# ISD91200B_v1 register map
File version: 1.0
Registers are 32-bit, read-write, reset 0x0 unless marked. A register's access mark holds for its fields unless they carry their own. Offsets are from the block's base; [hi:lo] are bit positions; 'fields as' and 'values as' point back to an identical list.

## CLK — CLK Register Map
Base 0x50000200
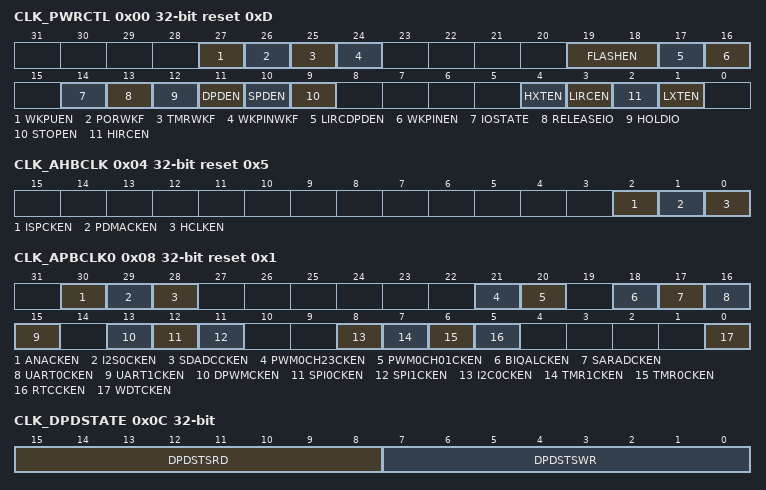
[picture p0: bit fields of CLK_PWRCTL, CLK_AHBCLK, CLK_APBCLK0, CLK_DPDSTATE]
0x00 CLK_PWRCTL reset 0xD (reset mask 0xFFFFFF) — System Power Control Register
  [27] WKPUEN — Wakeup Pin Pull-up Control. This signal is latched in deep power down and preserved.
    0=pull-up enable; 1=tri-state (default)
  [26] PORWKF — POR Wakeup Flag. Read Only. This flag indicates that wakeup of device was requested with a power-on reset. Flag is cleared when DPD mode is entered.
  [25] TMRWKF — Timer Wakeup Flag. Read Only. This flag indicates that wakeup of device was requested with TIMER count of the 10khz oscillator. Flag is cleared when DPD mode is entered.
  [24] WKPINWKF — Pin Wakeup Flag. Read Only. This flag indicates that wakeup of device was requested with a high to low transition of the WAKEUP pin. Flag is cleared when DPD mode is entered.
  [19:18] FLASHEN — Flash ROM Control Enable/Disable. Bit [19]: for Stop mode operation. Bit [18]: for Sleep mode operation. 1: Turn off flash. 0: Normal. Note: It takes 10us to turn on the flash to normal
  [17] LIRCDPDEN — OSC10k Enabled Control. Determines whether OSC10k is enabled in DPD mode. If OSC10k is disabled, device cannot wake from DPD with SELWKTMR delay.
    0=enabled; 1=disabled
  [16] WKPINEN — Wakeup Pin Enabled Control. Determines whether WAKEUP pin is enabled in DPD mode.
    0=enabled; 1=disabled
  [14] IOSTATE — '1': IO held from SPD '0': IO released.
  [13] RELEASEIO — Write '1' to this bit to release IO state after exiting SPD if hold request was made with the HOLD_IO bit.
  [12] HOLDIO — When entering SPD mode, IO state is automatically held If this bit is set to '1' then this sate upon resuming full power mode will be hold until the RELEASE_IO bit is written '1'
  [11] DPDEN — Deep Power Down (DPD) Bit. Set to '1' and issue WFI/WFE instruction to enter DPD mode.
  [10] SPDEN — Standby Power Down (SPD) Bit. Set to '1' and issue WFI/WFE instruction to enter SPD mode.
  [9] STOPEN — Stop. Set to '1' and issue WFI/WFE instruction to enter STOP mode.
  [4] HXTEN — HXT Oscillator Enable Bit
    0=disable (default); 1=enable
  [3] LIRCEN — LIRC Oscillator Enable Bit
    0=disable; 1=enable (default)
  [2] HIRCEN — HIRC Oscillator Enable Bit
    0=disable; 1=enable (default)
  [1] LXTEN — External 32.768 KHz Crystal Enable Bit
    0=disable (default); 1=enable
0x04 CLK_AHBCLK reset 0x5 — AHB Device Clock Enable Control Register
  [2] ISPCKEN — Flash ISP Controller Clock Enable Control
    0=To disable the Flash ISP engine clock; 1=To enable the Flash ISP engine clock
  [1] PDMACKEN — PDMA Controller Clock Enable Control
    0=To disable the PDMA engine clock; 1=To enable the PDMA engine clock
  [0] HCLKEN — CPU Clock Enable (HCLK). Must be left as 1 for normal operation.
0x08 CLK_APBCLK0 reset 0x1 — APB Device Clock Enable Control Register
  [all] fields
    0=Disable; 1=Enable
  [30] ANACKEN — Analog Block Clock Enable Control
  [29] I2S0CKEN — I2S Clock Enable Control
  [28] SDADCCKEN — Delta-Sigma Analog-digital-converter (ADC) Enable Control
  [21] PWM0CH23CKEN — PWM0CH2 and PWM0CH3 Block Clock Enable Control
  [20] PWM0CH01CKEN — PWM0CH0 and PWM0CH1 Block Clock Enable Control
  [18] BIQALCKEN — BIQ and ALC Clock Enable Control
  [17] SARADCKEN — SAR Analog-digital-converter (ADC) Clock Enable Control
  [16] UART0CKEN — UART0 Clock Enable Control
  [15] UART1CKEN — UART1 Clock Enable Control
  [13] DPWMCKEN — Differential PWM Speaker Driver Clock Enable Control
  [12] SPI0CKEN — SPI0 Clock Enable Control
  [11] SPI1CKEN — SPI1 Clock Enable Control
  [8] I2C0CKEN — I2C0 Clock Enable Control
  [7] TMR1CKEN — Timer1 Clock Enable Control
  [6] TMR0CKEN — Timer0 Clock Enable Control
  [5] RTCCKEN — Real-time-clock APB Interface Clock Control
  [0] WDTCKEN — Watchdog Clock Enable Control
0x0C CLK_DPDSTATE (reset mask 0xFFFF00FF) — Deep Power Down State Register
  [15:8] DPDSTSRD — DPD State Read Back. Read back of CLK_DPDSTATE register. This register was preserved from last DPD event .
  [7:0] DPDSTSWR — DPD State Write Register. Read back of CLK_DPDSTATE register. This register was preserved from last DPD event .
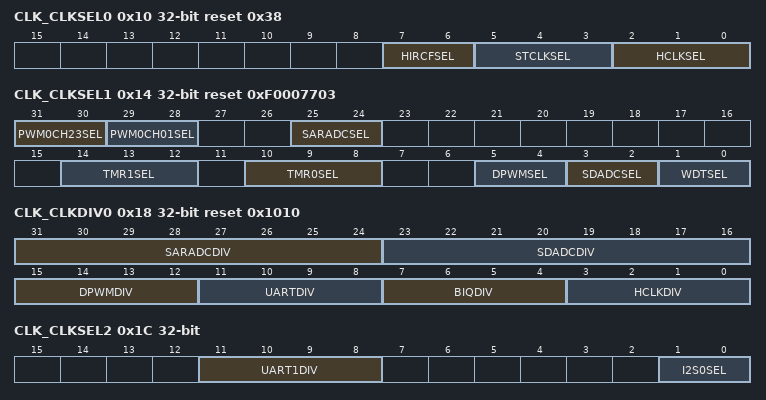
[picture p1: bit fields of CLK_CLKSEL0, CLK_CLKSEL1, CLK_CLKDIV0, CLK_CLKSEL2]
0x10 CLK_CLKSEL0 reset 0x38 — Clock Source Select Control Register 0
  [7:6] HIRCFSEL — High Frequency RC Oscilltor Frequency Select Register. These bits are protected, to write to bits first perform the unlock sequence.
    0=Trim for 49.152MHz selected; 1=Trim for 32.768MHz selected; 2=Trim for reserved
  [5:3] STCLKSEL — MCU Cortex_M0 SYST Clock Source Select. These bits are protected, to write to bits first perform the unlock sequence. Note that to use STCLKSEL as source of SysTic timer the CLKSRC bit of SYST_CSR must be set to 0.
    0=clock source from LIRC; 1=clock source from LXT. clock source from HCLK÷2 (Default); 2=clock source from LIRC divided by 2; 3=clock source from HIRC divided by 2
  [2:0] HCLKSEL — HCLK Clock Source Select. Ensure that related clock sources (pre-select and new-select) are enabled before updating register. These bits are protected, to write to bits first perform the unlock sequence.
    0=clock source from HIRC. (deafult); 1=clock source from LXT; 2=clock source from LIRC; 3=clock source from HXT
0x14 CLK_CLKSEL1 reset 0xF0007703 — Clock Source Select Control Register 1
  [31:30] PWM0CH23SEL — PWM0CH23 Clock Source Select. PWM0 CH2 and CH3 uses the same clock source, and pre-scaler
    0=clock source from LIRC; 1=clock source from LXT; 2=clock source from HCLK; 3=clock source from HIRC.(default)
  [29:28] PWM0CH01SEL — PWM0CH01 Clock Source Select. PWM0 CH0 and CH1 uses the same clock source, and pre-scaler
    values as PWM0CH23SEL
  [25:24] SARADCSEL — SAR ADC Clock Source Select
    0=clock source from HCLK (default); 1=clock source from LIRC; 2=clock source from HIRC; 3=clock source from LXT
  [14:12] TMR1SEL — TIMER1 Clock Source Select
    0=clock source from LIRC; 1=clock source from LXT. clock source from HCLK.(default); 2=clock source from HXT; 3=clock source from external pin (GPIOA[11])
  [10:8] TMR0SEL — TIMER0 Clock Source Select
    0=clock source from LIRC; 1=clock source from LXT. clock source from internal HCLK.(default); 2=clock source from HXT; 3=clock source from external pin (GPIOA[10])
  [5:4] DPWMSEL — Differential Speaker Driver PWM Clock Source Select
    0=clock source from HCLK/(DPWMDIV+1). (default); 1=clock source from HXT. Reserved
  [3:2] SDADCSEL — SD ADC Clock Source Select (output is MCLK after clock enable)
    0=clock source from HCLK/(SDADCDIV+1). (default); 1=clock source from HXT. Reserved
  [1:0] WDTSEL — WDT Clock Source Select
    0=clock source from HIRC; 1=clock source from LXT; 2=clock source from HCLK/2048 clock; 3=clock source from LIRC.(default)
0x18 CLK_CLKDIV0 reset 0x1010 — Clock Divider Number Register
  [31:24] SARADCDIV — SARADC Clock Divide Number From ADC Clock Source
  [23:16] SDADCDIV — SDADC Clock Divide Number From ADC Clock Source
  [15:12] DPWMDIV — DPWM Clock Divide Number From HCLK Clock Source
  [11:8] UARTDIV — UART Clock Divide Number From UART Clock Source
  [7:4] BIQDIV — BIQ Clock Divide Number From HCLK Clock Source
  [3:0] HCLKDIV — HCLK Clock Divide Number From HCLK Clock Source
0x1C CLK_CLKSEL2 — Clock Source Select Control Register 2
  [11:8] UART1DIV — UART1 Clock Divide Number From UART Clock Source
  [1:0] I2S0SEL — I2S0 Clock Source Select
    0=clock source from internal 10kHz oscillator.(default); 1=clock source from external 32kHz crystal clock; 2=clock source from HCLK; 3=clock source from HIRC
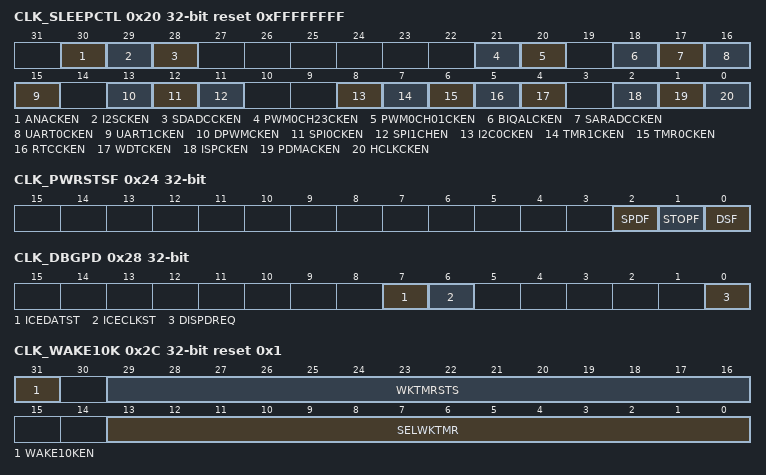
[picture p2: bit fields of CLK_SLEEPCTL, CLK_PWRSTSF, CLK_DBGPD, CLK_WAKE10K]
0x20 CLK_SLEEPCTL reset 0xFFFFFFFF — Sleep Clock Source Select Register
  [all] fields
    0=Disable; 1=Enable
  [30] ANACKEN — Analog Block Sleep Clock Enable Control
  [29] I2SCKEN — I2S Sleep Clock Enable Control
  [28] SDADCCKEN — Delta-Sigma Analog-digital-converter (ADC) Sleep Clock Enable Control
  [21] PWM0CH23CKEN — PWM0CH2 and PWM0CH3 Block Sleep Clock Enable Control
  [20] PWM0CH01CKEN — PWM0CH0 and PWM0CH1 Block Sleep Clock Enable Control
  [18] BIQALCKEN — BIQ and ALCSleep Clock Enable Control
  [17] SARADCCKEN — SARADC Sleep Clock Enable Control
  [16] UART0CKEN — UART0 Sleep Clock Enable Control
  [15] UART1CKEN — UART1 Sleep Clock Enable Control
  [13] DPWMCKEN — Differential PWM Speaker Driver Sleep Clock Enable Control
  [12] SPI0CKEN — SPI0 Sleep Clock Enable Control
  [11] SPI1CHEN — SPI1 Sleep Clock Enable Control
  [8] I2C0CKEN — I2C0 Sleep Clock Enable Control
  [7] TMR1CKEN — Timer1 Sleep Clock Enable Control
  [6] TMR0CKEN — Timer0 Sleep Clock Enable Control
  [5] RTCCKEN — Real-time- Sleep Clock APB Interface Clock Control
  [4] WDTCKEN — Watchdog Sleep Clock Enable Control
  [2] ISPCKEN — Flash ISP Controller Sleep Clock Enable Control
  [1] PDMACKEN — PDMA Controller Sleep Clock Enable Control
  [0] HCLKCKEN — CPU Clock Sleep Enable (HCLK). Must be left as '1' for normal operation.
0x24 CLK_PWRSTSF — Power State Flag Register
  [2] SPDF — Powered Down Flag. This flag is set if core logic was powered down to Standby (SPD). Write '1' to clear flag.
  [1] STOPF — Stop Flag. This flag is set if core logic was stopped but not powered down. Write '1' to clear flag.
  [0] DSF — Deep Sleep Flag. This flag is set if core logic was placed in Deep Sleep mode. Write '1' to clear flag.
0x28 CLK_DBGPD (reset mask 0xFFFFFF00) — Debug Port Power Down Disable Register
  [7] ICEDATST — ICEDATST Pin State. Read Only. Current state of ICE_DAT pin.
  [6] ICECLKST — ICECLKST Pin State. Read Only. Current state of ICE_CLK pin.
  [0] DISPDREQ — Disable Power Down
    0=Enable power down requests; 1=Disable power down requests
0x2C CLK_WAKE10K reset 0x1 — Deep Power Down 10K Wakeup Timer
  [31] WAKE10KEN — Enable WAKE from DPD on 10kHz timer
  [29:16] WKTMRSTS — Current Wakeup Timer Setting. Read-Only. Read back of the current WAKEUP timer setting. This value is updated with SELWKTMR upon entering DPD mode.
  [13:0] SELWKTMR — Select Wakeup Timer. WAKEUP after 64* (SELWKTMR+1) OSC10k clocks (6.4 * (SELWKTMR+1) ms)
